AUTOSAR XML (schema 00053)
standard types defined: boolean
package /Services
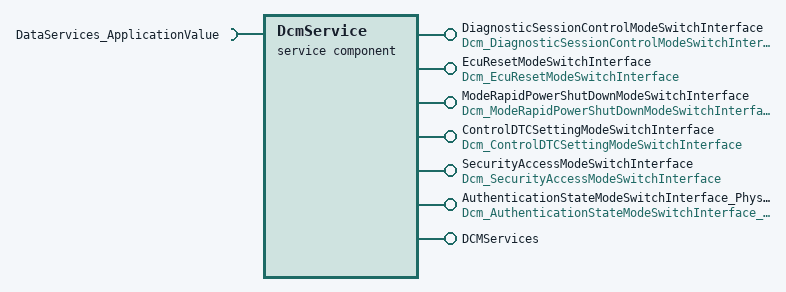
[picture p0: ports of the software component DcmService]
  service sw component type DcmService
    require port DataServices_ApplicationValue: client-com-spec=ReadData, required-interface=DataServices_ApplicationValue
    7 x provide port:
      DiagnosticSessionControlModeSwitchInterface: mode-switch-sender-com-spec{enhanced-mode-api=false, mode-group=diagnosticSession}, provided-interface=Dcm_DiagnosticSessionControlModeSwitchInterface
      EcuResetModeSwitchInterface: mode-switch-sender-com-spec{enhanced-mode-api=false, mode-group=ecuReset}, provided-interface=Dcm_EcuResetModeSwitchInterface
      ModeRapidPowerShutDownModeSwitchInterface: mode-switch-sender-com-spec{enhanced-mode-api=false, mode-group=modeRapidPowerShutDown}, provided-interface=Dcm_ModeRapidPowerShutDownModeSwitchInterface
      ControlDTCSettingModeSwitchInterface: mode-switch-sender-com-spec{enhanced-mode-api=false, mode-group=controlDTCSetting}, provided-interface=Dcm_ControlDTCSettingModeSwitchInterface
      SecurityAccessModeSwitchInterface: mode-switch-sender-com-spec{enhanced-mode-api=false, mode-group=securityAccess}, provided-interface=Dcm_SecurityAccessModeSwitchInterface
      AuthenticationStateModeSwitchInterface_Physical: mode-switch-sender-com-spec{enhanced-mode-api=false, mode-group=authenticationState}, provided-interface=Dcm_AuthenticationStateModeSwitchInterface_Physical
      DCMServices: provided-interface=DCMServices
        provided-com-specs:
          operation=GetSecurityLevel, queue-length=1
          operation=GetSesCtrlType, queue-length=1
          operation=ResetToDefaultSession, queue-length=1
          operation=SetActiveDiagnostic, queue-length=1
    behavior Behavior: data-type-mapping=DcmModeTypes
      4 x operation invoked event:
        InvokeGetSecurityLevel: start-on-event=GetSecurityLevel, operation=DCMServices.GetSecurityLevel
        InvokeGetSesCtrlType: start-on-event=GetSesCtrlType, operation=DCMServices.GetSesCtrlType
        InvokeResetToDefaultSession: start-on-event=ResetToDefaultSession, operation=DCMServices.ResetToDefaultSession
        InvokeSetActiveDiagnostic: start-on-event=SetActiveDiagnostic, operation=DCMServices.SetActiveDiagnostic
      5 x runnable:
        DcmReadData: symbol=DcmService_ReadData
          sync call ReadApplicationValue: operation=DataServices_ApplicationValue.ReadData
        GetSecurityLevel: can-be-invoked-concurrently=true, symbol=Dcm_GetSecurityLevel
        GetSesCtrlType: can-be-invoked-concurrently=true, symbol=Dcm_GetSesCtrlType
        ResetToDefaultSession: can-be-invoked-concurrently=true, symbol=Dcm_ResetToDefaultSession
        SetActiveDiagnostic: can-be-invoked-concurrently=true, symbol=Dcm_SetActiveDiagnostic
  mode switch interface Dcm_DiagnosticSessionControlModeSwitchInterface: is-service=true
    mode group diagnosticSession: type=DcmDiagnosticSessionControl
  data type mapping set DcmModeTypes
    mode-request-type-maps:
      implementation-data-type=Rte_ModeType_DcmDiagnosticSessionControl, mode-group=DcmDiagnosticSessionControl
      implementation-data-type=Rte_ModeType_DcmEcuReset, mode-group=DcmEcuReset
      implementation-data-type=Rte_ModeType_DcmModeRapidPowerShutDown, mode-group=DcmModeRapidPowerShutDown
      implementation-data-type=Rte_ModeType_DcmControlDTCSetting, mode-group=DcmControlDTCSetting
      implementation-data-type=Rte_ModeType_DcmSecurityAccess, mode-group=DcmSecurityAccess
      implementation-data-type=Rte_ModeType_DcmAuthenticationState_Physical, mode-group=DcmAuthenticationState_Physical
  5 x mode switch interface, all with is-service=true:
    Dcm_EcuResetModeSwitchInterface
      mode group ecuReset: type=DcmEcuReset
    Dcm_ModeRapidPowerShutDownModeSwitchInterface
      mode group modeRapidPowerShutDown: type=DcmModeRapidPowerShutDown
    Dcm_ControlDTCSettingModeSwitchInterface
      mode group controlDTCSetting: type=DcmControlDTCSetting
    Dcm_SecurityAccessModeSwitchInterface
      mode group securityAccess: type=DcmSecurityAccess
    Dcm_AuthenticationStateModeSwitchInterface_Physical
      mode group authenticationState: type=DcmAuthenticationState_Physical
  client server interface DCMServices: is-service=true, service-kind=DIAGNOSTIC-COMMUNICATION-MANAGER
    4 x operation:
      GetSecurityLevel: possible-error=[E_OK, E_NOT_OK]
        arg SecLevel: type=Dcm_SecLevelType, direction=OUT
      GetSesCtrlType: possible-error=[E_OK, E_NOT_OK]
        arg SesCtrlType: type=Dcm_SesCtrlType, direction=OUT
      ResetToDefaultSession: possible-error=[E_OK, E_NOT_OK]
      SetActiveDiagnostic: possible-error=E_OK
        arg active: type=boolean, direction=IN
    error E_OK: error-code=0
    error E_NOT_OK: error-code=1
  impl type Dcm_SecLevelType: category=VALUE, base-type=Native7, type-emitter=Rte_Dcm_Type.h
  impl type Dcm_SesCtrlType: category=VALUE, base-type=Native7, type-emitter=Rte_Dcm_Type.h
  base type BooleanBase: category=FIXED_LENGTH, base-type-size=8, base-type-encoding=BOOLEAN, native-declaration=boolean
  swc implementation DcmServicesImplementation: programming-language=C, behavior=Behavior
  swc bsw mapping DcmServicesMapping: bsw-behavior=Behavior, swc-behavior=Behavior
    runnable-mappings:
      bsw-entity=Dcm_GetSecurityLevel_Entity, swc-runnable=GetSecurityLevel
      bsw-entity=Dcm_GetSesCtrlType_Entity, swc-runnable=GetSesCtrlType
      bsw-entity=Dcm_ResetToDefaultSession_Entity, swc-runnable=ResetToDefaultSession
      bsw-entity=Dcm_SetActiveDiagnostic_Entity, swc-runnable=SetActiveDiagnostic
  base type DcmNativeGetSecurityLevel: category=FIXED_LENGTH, base-type-size=8, base-type-encoding=NONE, native-declaration=Dcm_SecLevelType *
  base type DcmNativeGetSesCtrlType: category=FIXED_LENGTH, base-type-size=8, base-type-encoding=NONE, native-declaration=Dcm_SesCtrlType *
  base type DcmNativeSetActiveDiagnostic: category=FIXED_LENGTH, base-type-size=8, base-type-encoding=NONE, native-declaration=boolean
